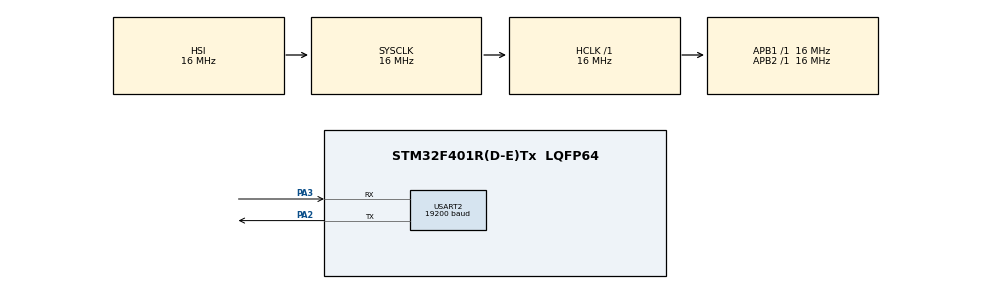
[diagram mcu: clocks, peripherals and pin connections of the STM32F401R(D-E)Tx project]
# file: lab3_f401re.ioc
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Mcu.Family=STM32F4
RCC.VCOOutputFreq_Value=192000000
RCC.APB2Freq_Value=16000000
RCC.CortexFreq_Value=16000000
Mcu.Name=STM32F401R(D-E)Tx
PA2.Signal=USART2_TX
NVIC.USART2_IRQn=true\:0\:0\:false\:false\:true\:true\:true
RCC.SYSCLKFreq_VALUE=16000000
USART2.BaudRate=19200
Mcu.Package=LQFP64
ProjectManager.StackSize=0x400
USART2.VirtualMode=VM_ASYNC
PA3.Mode=Asynchronous
ProjectManager.HeapSize=0x200
ProjectManager.TargetToolchain=STM32CubeIDE
RCC.HSI_VALUE=16000000
NVIC.PriorityGroup=NVIC_PRIORITYGROUP_4
PA2.Mode=Asynchronous
RCC.LSE_VALUE=32768
RCC.APB1Freq_Value=16000000
RCC.AHBFreq_Value=16000000
RCC.HSE_VALUE=25000000
PA3.Signal=USART2_RX
board=custom

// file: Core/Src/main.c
/* USER CODE BEGIN Header */
/**
  ******************************************************************************
  * @file           : main.c
  * @brief          : Main program body
  ******************************************************************************
  * @attention
  *
  * <h2><center>&copy; Copyright (c) 2023 STMicroelectronics.
  * All rights reserved.</center></h2>
  *
  * This software component is licensed by ST under BSD 3-Clause license,
  * the "License"; You may not use this file except in compliance with the
  * License. You may obtain a copy of the License at:
  *                        opensource.org/licenses/BSD-3-Clause
  *
  ******************************************************************************
  */
/* USER CODE END Header */
#include "main.h"

/* USER CODE BEGIN Includes */
#include <stdio.h>
#include <math.h>
/* USER CODE END Includes */

UART_HandleTypeDef huart2;

/* USER CODE BEGIN PV */
int n;
int undef_flag = 1;
int n_r;
int res_n;
uint8_t rx_buffer[4];
char tx_buffer[5];
/* USER CODE END PV */

void SystemClock_Config(void);
static void MX_GPIO_Init(void);
static void MX_USART2_UART_Init(void);

int main(void)
{

  /* MCU Configuration--------------------------------------------------------*/

  /* Reset of all peripherals, Initializes the Flash interface and the Systick. */
  HAL_Init();

  /* Configure the system clock */
  SystemClock_Config();

  /* Initialize all configured peripherals */
  MX_GPIO_Init();
  MX_USART2_UART_Init();
  /* USER CODE BEGIN 2 */
  HAL_UART_Receive_IT(&huart2, rx_buffer, sizeof(rx_buffer));
  /* USER CODE END 2 */

  /* Infinite loop */
  while (1)
  {

  }
}

void SystemClock_Config(void)
{
  RCC_OscInitTypeDef RCC_OscInitStruct = {0};
  RCC_ClkInitTypeDef RCC_ClkInitStruct = {0};

  /** Configure the main internal regulator output voltage
  */
  __HAL_RCC_PWR_CLK_ENABLE();
  __HAL_PWR_VOLTAGESCALING_CONFIG(PWR_REGULATOR_VOLTAGE_SCALE2);
  /** Initializes the RCC Oscillators according to the specified parameters
  * in the RCC_OscInitTypeDef structure.
  */
  RCC_OscInitStruct.OscillatorType = RCC_OSCILLATORTYPE_HSI;
  RCC_OscInitStruct.HSIState = RCC_HSI_ON;
  RCC_OscInitStruct.HSICalibrationValue = RCC_HSICALIBRATION_DEFAULT;
  RCC_OscInitStruct.PLL.PLLState = RCC_PLL_NONE;
  if (HAL_RCC_OscConfig(&RCC_OscInitStruct) != HAL_OK)
  {
    Error_Handler();
  }
  /** Initializes the CPU, AHB and APB buses clocks
  */
  RCC_ClkInitStruct.ClockType = RCC_CLOCKTYPE_HCLK|RCC_CLOCKTYPE_SYSCLK
                              |RCC_CLOCKTYPE_PCLK1|RCC_CLOCKTYPE_PCLK2;
  RCC_ClkInitStruct.SYSCLKSource = RCC_SYSCLKSOURCE_HSI;
  RCC_ClkInitStruct.AHBCLKDivider = RCC_SYSCLK_DIV1;
  RCC_ClkInitStruct.APB1CLKDivider = RCC_HCLK_DIV1;
  RCC_ClkInitStruct.APB2CLKDivider = RCC_HCLK_DIV1;

  if (HAL_RCC_ClockConfig(&RCC_ClkInitStruct, FLASH_LATENCY_0) != HAL_OK)
  {
    Error_Handler();
  }
}

static void MX_USART2_UART_Init(void)
{

  huart2.Instance = USART2;
  huart2.Init.BaudRate = 19200;
  huart2.Init.WordLength = UART_WORDLENGTH_8B;
  huart2.Init.StopBits = UART_STOPBITS_1;
  huart2.Init.Parity = UART_PARITY_NONE;
  huart2.Init.Mode = UART_MODE_TX_RX;
  huart2.Init.HwFlowCtl = UART_HWCONTROL_NONE;
  huart2.Init.OverSampling = UART_OVERSAMPLING_16;
  if (HAL_UART_Init(&huart2) != HAL_OK)
  {
    Error_Handler();
  }

}

static void MX_GPIO_Init(void)
{

  /* GPIO Ports Clock Enable */
  __HAL_RCC_GPIOA_CLK_ENABLE();

}

/* USER CODE BEGIN 4 */
void HAL_UART_RxCpltCallback(UART_HandleTypeDef *huart) {
	n_r = ((int)rx_buffer[1] - 48) * 10 + ((int)rx_buffer[2] - 48);  // since the numbers (digits) start from 48 in ASCII code
	if (n_r == 0) {
		undef_flag = 1;
		sprintf(tx_buffer, "N--E");
	}
	else {
		undef_flag = 0;
		res_n = (int)round(log(n_r));
		n = res_n;
		sprintf(tx_buffer, "N0%uE", res_n);
	}
	HAL_UART_Transmit_IT(&huart2, (uint8_t*)tx_buffer, sizeof(tx_buffer));
	HAL_UART_Receive_IT(&huart2, rx_buffer, sizeof(rx_buffer));
}
/* USER CODE END 4 */

void Error_Handler(void)
{
  __disable_irq();
  while (1)
  {
  }
}

/************************ (C) COPYRIGHT STMicroelectronics *****END OF FILE****/
